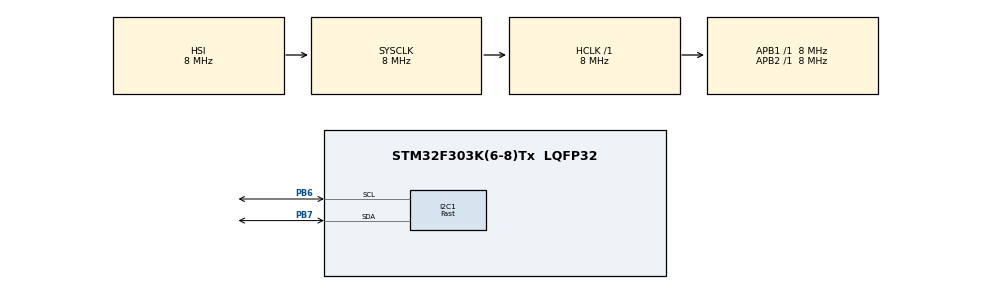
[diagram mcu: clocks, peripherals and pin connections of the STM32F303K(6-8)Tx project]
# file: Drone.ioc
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I2C1.I2C_Speed_Mode=I2C_Fast
I2C1.Timing=0x0000020B
Mcu.Family=STM32F3
Mcu.Name=STM32F303K(6-8)Tx
Mcu.Package=LQFP32
NVIC.PriorityGroup=NVIC_PRIORITYGROUP_4
PB6.Mode=I2C
PB6.Signal=I2C1_SCL
PB7.Mode=I2C
PB7.Signal=I2C1_SDA
ProjectManager.HeapSize=0x200
ProjectManager.StackSize=0x400
ProjectManager.TargetToolchain=MDK-ARM V5
RCC.AHBFreq_Value=8000000
RCC.APB1Freq_Value=8000000
RCC.APB2Freq_Value=8000000
RCC.CortexFreq_Value=8000000
RCC.HSE_VALUE=8000000
RCC.HSI_VALUE=8000000
RCC.SYSCLKFreq_VALUE=8000000
board=NUCLEO-F303K8

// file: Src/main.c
/* USER CODE BEGIN Header */
/**
  ******************************************************************************
  * @file           : main.c
  * @brief          : Main program body
  ******************************************************************************
  * @attention
  *
  * <h2><center>&copy; Copyright (c) 2020 STMicroelectronics.
  * All rights reserved.</center></h2>
  *
  * This software component is licensed by ST under BSD 3-Clause license,
  * the "License"; You may not use this file except in compliance with the
  * License. You may obtain a copy of the License at:
  *                        opensource.org/licenses/BSD-3-Clause
  *
  ******************************************************************************
  */
/* USER CODE END Header */

#include "main.h"
#include "i2c.h"
#include "gpio.h"

/* USER CODE BEGIN Includes */
#include "tm_stm32_mpu6050.h"

/* USER CODE END Includes */

/* USER CODE BEGIN PV */
/* MPU6050 working structure */
TM_MPU6050_t MPU6050;
//TM_MPU6050_Result_t _status = TM_MPU6050_Result_Error;
/* USER CODE END PV */

void SystemClock_Config(void);

int main(void)
{

  /* MCU Configuration--------------------------------------------------------*/

  /* Reset of all peripherals, Initializes the Flash interface and the Systick. */
  HAL_Init();

  /* Configure the system clock */
  SystemClock_Config();

  /* Initialize all configured peripherals */
  MX_GPIO_Init();
  MX_I2C1_Init();
  /* USER CODE BEGIN 2 */
	TM_MPU6050_Init(&MPU6050, TM_MPU6050_Device_0, TM_MPU6050_Accelerometer_8G, TM_MPU6050_Gyroscope_250s);
	//_status = TM_MPU6050_Calibrate(&MPU6050);
	//for(int i = 0; i < 5000 ; i++); //Tempo

//	if(_status != TM_MPU6050_Result_Ok){ //Config MPU failed
//		while(1);
//	}

  /* USER CODE END 2 */

  /* Infinite loop */
  /* USER CODE BEGIN WHILE */
  while (1)
  {
		/* Read everything from device */
		TM_MPU6050_ReadAll(&MPU6050);

		//for(int i = 0; i < 5000 ; i++); //Tempo
    /* USER CODE END WHILE */

  }
}

void SystemClock_Config(void)
{
  RCC_OscInitTypeDef RCC_OscInitStruct = {0};
  RCC_ClkInitTypeDef RCC_ClkInitStruct = {0};
  RCC_PeriphCLKInitTypeDef PeriphClkInit = {0};

  /** Initializes the CPU, AHB and APB busses clocks
  */
  RCC_OscInitStruct.OscillatorType = RCC_OSCILLATORTYPE_HSI;
  RCC_OscInitStruct.HSIState = RCC_HSI_ON;
  RCC_OscInitStruct.HSICalibrationValue = RCC_HSICALIBRATION_DEFAULT;
  RCC_OscInitStruct.PLL.PLLState = RCC_PLL_NONE;
  if (HAL_RCC_OscConfig(&RCC_OscInitStruct) != HAL_OK)
  {
    Error_Handler();
  }
  /** Initializes the CPU, AHB and APB busses clocks
  */
  RCC_ClkInitStruct.ClockType = RCC_CLOCKTYPE_HCLK|RCC_CLOCKTYPE_SYSCLK
                              |RCC_CLOCKTYPE_PCLK1|RCC_CLOCKTYPE_PCLK2;
  RCC_ClkInitStruct.SYSCLKSource = RCC_SYSCLKSOURCE_HSI;
  RCC_ClkInitStruct.AHBCLKDivider = RCC_SYSCLK_DIV1;
  RCC_ClkInitStruct.APB1CLKDivider = RCC_HCLK_DIV1;
  RCC_ClkInitStruct.APB2CLKDivider = RCC_HCLK_DIV1;

  if (HAL_RCC_ClockConfig(&RCC_ClkInitStruct, FLASH_LATENCY_0) != HAL_OK)
  {
    Error_Handler();
  }
  PeriphClkInit.PeriphClockSelection = RCC_PERIPHCLK_I2C1;
  PeriphClkInit.I2c1ClockSelection = RCC_I2C1CLKSOURCE_HSI;
  if (HAL_RCCEx_PeriphCLKConfig(&PeriphClkInit) != HAL_OK)
  {
    Error_Handler();
  }
}

void Error_Handler(void)
{
}

/************************ (C) COPYRIGHT STMicroelectronics *****END OF FILE****/
